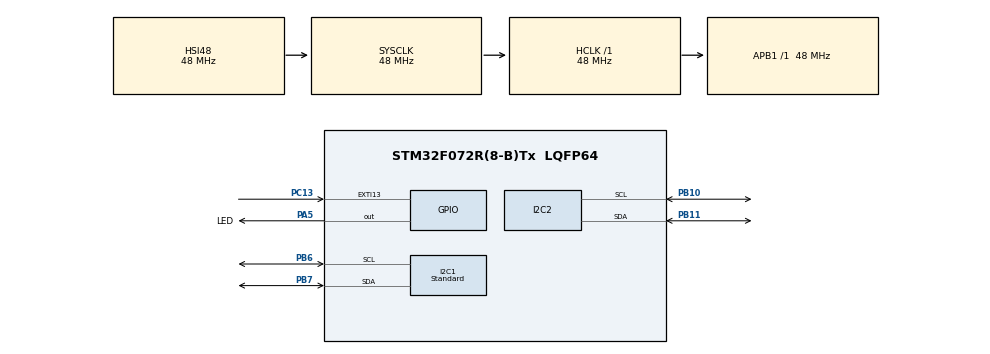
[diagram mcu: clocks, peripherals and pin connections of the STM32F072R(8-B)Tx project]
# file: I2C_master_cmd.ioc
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Dma.I2C1_RX.0.Direction=DMA_PERIPH_TO_MEMORY
Dma.I2C1_RX.0.Instance=DMA1_Channel3
Dma.I2C1_RX.0.MemDataAlignment=DMA_MDATAALIGN_BYTE
Dma.I2C1_RX.0.MemInc=DMA_MINC_ENABLE
Dma.I2C1_RX.0.Mode=DMA_NORMAL
Dma.I2C1_RX.0.PeriphDataAlignment=DMA_PDATAALIGN_BYTE
Dma.I2C1_RX.0.PeriphInc=DMA_PINC_DISABLE
Dma.I2C1_RX.0.Priority=DMA_PRIORITY_LOW
Dma.I2C1_TX.1.Direction=DMA_MEMORY_TO_PERIPH
Dma.I2C1_TX.1.Instance=DMA1_Channel2
Dma.I2C1_TX.1.MemDataAlignment=DMA_MDATAALIGN_BYTE
Dma.I2C1_TX.1.MemInc=DMA_MINC_ENABLE
Dma.I2C1_TX.1.Mode=DMA_NORMAL
Dma.I2C1_TX.1.PeriphDataAlignment=DMA_PDATAALIGN_BYTE
Dma.I2C1_TX.1.PeriphInc=DMA_PINC_DISABLE
Dma.I2C1_TX.1.Priority=DMA_PRIORITY_LOW
Dma.I2C2_RX.2.Direction=DMA_PERIPH_TO_MEMORY
Dma.I2C2_RX.2.Instance=DMA1_Channel5
Dma.I2C2_RX.2.MemDataAlignment=DMA_MDATAALIGN_BYTE
Dma.I2C2_RX.2.MemInc=DMA_MINC_ENABLE
Dma.I2C2_RX.2.Mode=DMA_NORMAL
Dma.I2C2_RX.2.PeriphDataAlignment=DMA_PDATAALIGN_BYTE
Dma.I2C2_RX.2.PeriphInc=DMA_PINC_DISABLE
Dma.I2C2_RX.2.Priority=DMA_PRIORITY_LOW
Dma.I2C2_TX.3.Direction=DMA_MEMORY_TO_PERIPH
Dma.I2C2_TX.3.Instance=DMA1_Channel4
Dma.I2C2_TX.3.MemDataAlignment=DMA_MDATAALIGN_BYTE
Dma.I2C2_TX.3.MemInc=DMA_MINC_ENABLE
Dma.I2C2_TX.3.Mode=DMA_NORMAL
Dma.I2C2_TX.3.PeriphDataAlignment=DMA_PDATAALIGN_BYTE
Dma.I2C2_TX.3.PeriphInc=DMA_PINC_DISABLE
Dma.I2C2_TX.3.Priority=DMA_PRIORITY_LOW
Dma.Request0=I2C1_RX
Dma.Request1=I2C1_TX
Dma.Request2=I2C2_RX
Dma.Request3=I2C2_TX
I2C1.DualAddressMode=I2C_DUALADDRESS_ENABLE
I2C1.I2C_Fall_Time=0
I2C1.I2C_Rise_Time=0
I2C1.I2C_Speed_Mode=I2C_Standard
I2C1.NoStretchMode=I2C_NOSTRETCH_DISABLE
I2C2.NoStretchMode=I2C_NOSTRETCH_DISABLE
I2C2.Timing=0x20303E5D
Mcu.Family=STM32F0
Mcu.Name=STM32F072R(8-B)Tx
Mcu.Package=LQFP64
NVIC.DMA1_Channel2_3_IRQn=true\:0\:0\:false\:false\:true\:false\:true\:true
NVIC.DMA1_Channel4_5_6_7_IRQn=true\:0\:0\:false\:false\:true\:false\:true\:true
NVIC.EXTI4_15_IRQn=true\:0\:0\:false\:false\:true\:true\:true\:true
NVIC.I2C1_IRQn=true\:0\:0\:false\:false\:true\:true\:true\:true
NVIC.I2C2_IRQn=true\:0\:0\:false\:false\:true\:true\:true\:true
PA5.GPIO_Label=LED
PA5.GPIO_PuPd=GPIO_NOPULL
PA5.Signal=GPIO_Output
PB10.Mode=I2C
PB10.Signal=I2C2_SCL
PB11.Mode=I2C
PB11.Signal=I2C2_SDA
PB6.GPIO_Pu=GPIO_PULLUP
PB6.Mode=I2C
PB6.Signal=I2C1_SCL
PB7.GPIO_Pu=GPIO_PULLUP
PB7.Mode=I2C
PB7.Signal=I2C1_SDA
PC13.GPIO_ModeDefaultEXTI=GPIO_MODE_IT_FALLING
PC13.GPIO_PuPd=GPIO_PULLUP
PC13.Signal=GPXTI13
ProjectManager.HeapSize=0x200
ProjectManager.StackSize=0x400
ProjectManager.TargetToolchain=STM32CubeIDE
RCC.AHBFreq_Value=48000000
RCC.APB1Freq_Value=48000000
RCC.APB1TimFreq_Value=48000000
RCC.HCLKFreq_Value=48000000
RCC.SYSCLKFreq_VALUE=48000000
RCC.SYSCLKSource=RCC_SYSCLKSOURCE_HSI48
VP_CRC_VS_CRC.Mode=CRC_Activate
board=custom

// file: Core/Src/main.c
/* USER CODE BEGIN Header */
/**
  ******************************************************************************
  * @file           : main.c
  * @brief          : Main program body
  ******************************************************************************
  * @attention
  *
  * Copyright (c) 2024 STMicroelectronics.
  * All rights reserved.
  *
  * This software is licensed under terms that can be found in the LICENSE file
  * in the root directory of this software component.
  * If no LICENSE file comes with this software, it is provided AS-IS.
  *
  ******************************************************************************
  */
/* USER CODE END Header */
#include "main.h"

CRC_HandleTypeDef hcrc;

I2C_HandleTypeDef hi2c1;
I2C_HandleTypeDef hi2c2;
DMA_HandleTypeDef hdma_i2c1_rx;
DMA_HandleTypeDef hdma_i2c1_tx;
DMA_HandleTypeDef hdma_i2c2_rx;
DMA_HandleTypeDef hdma_i2c2_tx;

void SystemClock_Config(void);
static void MX_GPIO_Init(void);
static void MX_DMA_Init(void);
static void MX_I2C1_Init(void);
static void MX_I2C2_Init(void);
static void MX_CRC_Init(void);

int main(void)
{

  /* MCU Configuration--------------------------------------------------------*/

  /* Reset of all peripherals, Initializes the Flash interface and the Systick. */
  HAL_Init();

  /* Configure the system clock */
  SystemClock_Config();

  /* Initialize all configured peripherals */
  MX_GPIO_Init();
  MX_DMA_Init();
  MX_I2C1_Init();
  MX_I2C2_Init();
  MX_CRC_Init();
  /* USER CODE BEGIN 2 */
  I2CSlave_init();
  I2CMaster_init();
  /* USER CODE END 2 */

  /* Infinite loop */
  /* USER CODE BEGIN WHILE */
  while (1)
  {
	  I2CSlave_task();
	  I2CMaster_task();
    /* USER CODE END WHILE */

  }
}

void SystemClock_Config(void)
{
  RCC_OscInitTypeDef RCC_OscInitStruct = {0};
  RCC_ClkInitTypeDef RCC_ClkInitStruct = {0};
  RCC_PeriphCLKInitTypeDef PeriphClkInit = {0};

  /** Initializes the RCC Oscillators according to the specified parameters
  * in the RCC_OscInitTypeDef structure.
  */
  RCC_OscInitStruct.OscillatorType = RCC_OSCILLATORTYPE_HSI|RCC_OSCILLATORTYPE_HSI48;
  RCC_OscInitStruct.HSIState = RCC_HSI_ON;
  RCC_OscInitStruct.HSI48State = RCC_HSI48_ON;
  RCC_OscInitStruct.HSICalibrationValue = RCC_HSICALIBRATION_DEFAULT;
  RCC_OscInitStruct.PLL.PLLState = RCC_PLL_NONE;
  if (HAL_RCC_OscConfig(&RCC_OscInitStruct) != HAL_OK)
  {
    Error_Handler();
  }

  /** Initializes the CPU, AHB and APB buses clocks
  */
  RCC_ClkInitStruct.ClockType = RCC_CLOCKTYPE_HCLK|RCC_CLOCKTYPE_SYSCLK
                              |RCC_CLOCKTYPE_PCLK1;
  RCC_ClkInitStruct.SYSCLKSource = RCC_SYSCLKSOURCE_HSI48;
  RCC_ClkInitStruct.AHBCLKDivider = RCC_SYSCLK_DIV1;
  RCC_ClkInitStruct.APB1CLKDivider = RCC_HCLK_DIV1;

  if (HAL_RCC_ClockConfig(&RCC_ClkInitStruct, FLASH_LATENCY_1) != HAL_OK)
  {
    Error_Handler();
  }
  PeriphClkInit.PeriphClockSelection = RCC_PERIPHCLK_I2C1;
  PeriphClkInit.I2c1ClockSelection = RCC_I2C1CLKSOURCE_HSI;
  if (HAL_RCCEx_PeriphCLKConfig(&PeriphClkInit) != HAL_OK)
  {
    Error_Handler();
  }
}

static void MX_CRC_Init(void)
{

  hcrc.Instance = CRC;
  hcrc.Init.DefaultPolynomialUse = DEFAULT_POLYNOMIAL_ENABLE;
  hcrc.Init.DefaultInitValueUse = DEFAULT_INIT_VALUE_ENABLE;
  hcrc.Init.InputDataInversionMode = CRC_INPUTDATA_INVERSION_NONE;
  hcrc.Init.OutputDataInversionMode = CRC_OUTPUTDATA_INVERSION_DISABLE;
  hcrc.InputDataFormat = CRC_INPUTDATA_FORMAT_BYTES;
  if (HAL_CRC_Init(&hcrc) != HAL_OK)
  {
    Error_Handler();
  }

}

static void MX_I2C1_Init(void)
{

  hi2c1.Instance = I2C1;
  hi2c1.Init.Timing = 0x2000090E;
  hi2c1.Init.OwnAddress1 = 0;
  hi2c1.Init.AddressingMode = I2C_ADDRESSINGMODE_7BIT;
  hi2c1.Init.DualAddressMode = I2C_DUALADDRESS_ENABLE;
  hi2c1.Init.OwnAddress2 = 0;
  hi2c1.Init.OwnAddress2Masks = I2C_OA2_NOMASK;
  hi2c1.Init.GeneralCallMode = I2C_GENERALCALL_DISABLE;
  hi2c1.Init.NoStretchMode = I2C_NOSTRETCH_DISABLE;
  if (HAL_I2C_Init(&hi2c1) != HAL_OK)
  {
    Error_Handler();
  }

  /** Configure Analogue filter
  */
  if (HAL_I2CEx_ConfigAnalogFilter(&hi2c1, I2C_ANALOGFILTER_ENABLE) != HAL_OK)
  {
    Error_Handler();
  }

  /** Configure Digital filter
  */
  if (HAL_I2CEx_ConfigDigitalFilter(&hi2c1, 0) != HAL_OK)
  {
    Error_Handler();
  }

}

static void MX_I2C2_Init(void)
{

  hi2c2.Instance = I2C2;
  hi2c2.Init.Timing = 0x20303E5D;
  hi2c2.Init.OwnAddress1 = 0;
  hi2c2.Init.AddressingMode = I2C_ADDRESSINGMODE_7BIT;
  hi2c2.Init.DualAddressMode = I2C_DUALADDRESS_DISABLE;
  hi2c2.Init.OwnAddress2 = 0;
  hi2c2.Init.OwnAddress2Masks = I2C_OA2_NOMASK;
  hi2c2.Init.GeneralCallMode = I2C_GENERALCALL_DISABLE;
  hi2c2.Init.NoStretchMode = I2C_NOSTRETCH_DISABLE;
  if (HAL_I2C_Init(&hi2c2) != HAL_OK)
  {
    Error_Handler();
  }

  /** Configure Analogue filter
  */
  if (HAL_I2CEx_ConfigAnalogFilter(&hi2c2, I2C_ANALOGFILTER_ENABLE) != HAL_OK)
  {
    Error_Handler();
  }

  /** Configure Digital filter
  */
  if (HAL_I2CEx_ConfigDigitalFilter(&hi2c2, 0) != HAL_OK)
  {
    Error_Handler();
  }

}

static void MX_DMA_Init(void)
{

  /* DMA controller clock enable */
  __HAL_RCC_DMA1_CLK_ENABLE();

  /* DMA interrupt init */
  /* DMA1_Channel2_3_IRQn interrupt configuration */
  HAL_NVIC_SetPriority(DMA1_Channel2_3_IRQn, 0, 0);
  HAL_NVIC_EnableIRQ(DMA1_Channel2_3_IRQn);
  /* DMA1_Channel4_5_6_7_IRQn interrupt configuration */
  HAL_NVIC_SetPriority(DMA1_Channel4_5_6_7_IRQn, 0, 0);
  HAL_NVIC_EnableIRQ(DMA1_Channel4_5_6_7_IRQn);

}

static void MX_GPIO_Init(void)
{
  GPIO_InitTypeDef GPIO_InitStruct = {0};

  /* GPIO Ports Clock Enable */
  __HAL_RCC_GPIOC_CLK_ENABLE();
  __HAL_RCC_GPIOA_CLK_ENABLE();
  __HAL_RCC_GPIOB_CLK_ENABLE();

  /*Configure GPIO pin Output Level */
  HAL_GPIO_WritePin(LED_GPIO_Port, LED_Pin, GPIO_PIN_RESET);

  /*Configure GPIO pin : PC13 */
  GPIO_InitStruct.Pin = GPIO_PIN_13;
  GPIO_InitStruct.Mode = GPIO_MODE_IT_FALLING;
  GPIO_InitStruct.Pull = GPIO_PULLUP;
  HAL_GPIO_Init(GPIOC, &GPIO_InitStruct);

  /*Configure GPIO pin : LED_Pin */
  GPIO_InitStruct.Pin = LED_Pin;
  GPIO_InitStruct.Mode = GPIO_MODE_OUTPUT_PP;
  GPIO_InitStruct.Pull = GPIO_NOPULL;
  GPIO_InitStruct.Speed = GPIO_SPEED_FREQ_LOW;
  HAL_GPIO_Init(LED_GPIO_Port, &GPIO_InitStruct);

  /* EXTI interrupt init*/
  HAL_NVIC_SetPriority(EXTI4_15_IRQn, 0, 0);
  HAL_NVIC_EnableIRQ(EXTI4_15_IRQn);

}

void Error_Handler(void)
{
  __disable_irq();
  while (1)
  {
  }
}
